AUTOSAR XML (schema 4-0-3)
package /ComponentTypes
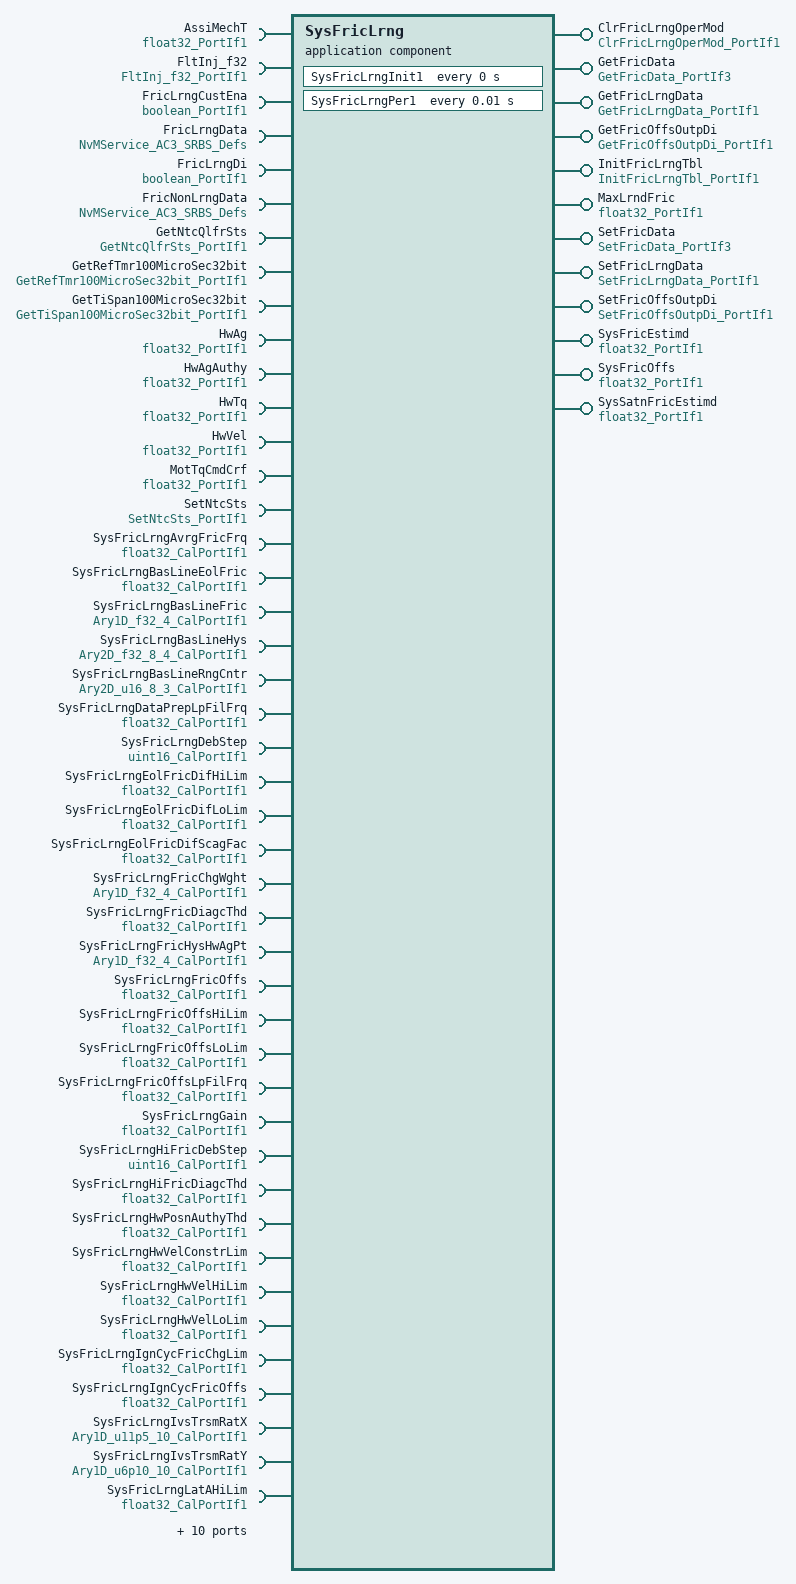
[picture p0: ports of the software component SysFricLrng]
  application sw component type SysFricLrng
    12 x provide port:
      ClrFricLrngOperMod: server-com-spec{operation=Oper, queue-length=1}, provided-interface=ClrFricLrngOperMod_PortIf1
      GetFricData: server-com-spec{operation=Oper, queue-length=1}, provided-interface=GetFricData_PortIf3
      GetFricLrngData: server-com-spec{operation=Oper, queue-length=1}, provided-interface=GetFricLrngData_PortIf1
      GetFricOffsOutpDi: server-com-spec{operation=Oper, queue-length=1}, provided-interface=GetFricOffsOutpDi_PortIf1
      InitFricLrngTbl: server-com-spec{operation=Oper, queue-length=1}, provided-interface=InitFricLrngTbl_PortIf1
      MaxLrndFric: nonqueued-sender-com-spec{data-element=Val, init-value=0}, provided-interface=float32_PortIf1
      SetFricData: server-com-spec{operation=Oper, queue-length=1}, provided-interface=SetFricData_PortIf3
      SetFricLrngData: server-com-spec{operation=Oper, queue-length=1}, provided-interface=SetFricLrngData_PortIf1
      SetFricOffsOutpDi: server-com-spec{operation=Oper, queue-length=1}, provided-interface=SetFricOffsOutpDi_PortIf1
      SysFricEstimd: nonqueued-sender-com-spec{data-element=Val, init-value=0}, provided-interface=float32_PortIf1
      SysFricOffs: nonqueued-sender-com-spec{data-element=Val, init-value=0}, provided-interface=float32_PortIf1
      SysSatnFricEstimd: nonqueued-sender-com-spec{data-element=Val, init-value=0}, provided-interface=float32_PortIf1
    54 x require port:
      AssiMechT: nonqueued-receiver-com-spec{data-element=Val, filter=data-filter-type=ALWAYS, init-value=0}, required-interface=float32_PortIf1
      FltInj_f32: client-com-spec=Oper, required-interface=FltInj_f32_PortIf1
      FricLrngCustEna: nonqueued-receiver-com-spec{data-element=Logl, filter=data-filter-type=ALWAYS, init-value=1}, required-interface=boolean_PortIf1
      FricLrngData: required-com-specs=[EraseBlock, GetErrorStatus, InvalidateNvBlock, ReadBlock, RestoreBlockDefaults, SetRamBlockStatus, WriteBlock], required-interface=NvMService_AC3_SRBS_Defs
      FricLrngDi: nonqueued-receiver-com-spec{data-element=Logl, filter=data-filter-type=ALWAYS, init-value=0}, required-interface=boolean_PortIf1
      FricNonLrngData: required-com-specs=[EraseBlock, GetErrorStatus, InvalidateNvBlock, ReadBlock, RestoreBlockDefaults, SetRamBlockStatus, WriteBlock], required-interface=NvMService_AC3_SRBS_Defs
      GetNtcQlfrSts: client-com-spec=Oper, required-interface=GetNtcQlfrSts_PortIf1
      GetRefTmr100MicroSec32bit: client-com-spec=Oper, required-interface=GetRefTmr100MicroSec32bit_PortIf1
      GetTiSpan100MicroSec32bit: client-com-spec=Oper, required-interface=GetTiSpan100MicroSec32bit_PortIf1
      HwAg: nonqueued-receiver-com-spec{data-element=Val, filter=data-filter-type=ALWAYS, init-value=0}, required-interface=float32_PortIf1
      HwAgAuthy: nonqueued-receiver-com-spec{data-element=Val, filter=data-filter-type=ALWAYS, init-value=0}, required-interface=float32_PortIf1
      HwTq: nonqueued-receiver-com-spec{data-element=Val, filter=data-filter-type=ALWAYS, init-value=0}, required-interface=float32_PortIf1
      HwVel: nonqueued-receiver-com-spec{data-element=Val, filter=data-filter-type=ALWAYS, init-value=0}, required-interface=float32_PortIf1
      MotTqCmdCrf: nonqueued-receiver-com-spec{data-element=Val, filter=data-filter-type=ALWAYS, init-value=0}, required-interface=float32_PortIf1
      SetNtcSts: client-com-spec=Oper, required-interface=SetNtcSts_PortIf1
      SysFricLrngAvrgFricFrq: parameter-require-com-spec{init-value=0.1, parameter=Val}, required-interface=float32_CalPortIf1
      SysFricLrngBasLineEolFric: parameter-require-com-spec{init-value=0, parameter=Val}, required-interface=float32_CalPortIf1
      SysFricLrngBasLineFric: parameter-require-com-spec{init-value=[0, 0, 0, 0], parameter=Ary1D}, required-interface=Ary1D_f32_4_CalPortIf1
      SysFricLrngBasLineHys: parameter-require-com-spec{init-value=8 x [0, 0, 0, 0], parameter=Ary2D}, required-interface=Ary2D_f32_8_4_CalPortIf1
      SysFricLrngBasLineRngCntr: parameter-require-com-spec{init-value=8 x [0, 0, 0], parameter=Ary2D}, required-interface=Ary2D_u16_8_3_CalPortIf1
      SysFricLrngDataPrepLpFilFrq: parameter-require-com-spec{init-value=30, parameter=Val}, required-interface=float32_CalPortIf1
      SysFricLrngDebStep: parameter-require-com-spec{init-value=656, parameter=Val}, required-interface=uint16_CalPortIf1
      SysFricLrngEolFricDifHiLim: parameter-require-com-spec{init-value=1, parameter=Val}, required-interface=float32_CalPortIf1
      SysFricLrngEolFricDifLoLim: parameter-require-com-spec{init-value=-1, parameter=Val}, required-interface=float32_CalPortIf1
      SysFricLrngEolFricDifScagFac: parameter-require-com-spec{init-value=0.8, parameter=Val}, required-interface=float32_CalPortIf1
      SysFricLrngFricChgWght: parameter-require-com-spec{init-value=[1, 1, 1, 1], parameter=Ary1D}, required-interface=Ary1D_f32_4_CalPortIf1
      SysFricLrngFricDiagcThd: parameter-require-com-spec{init-value=15, parameter=Val}, required-interface=float32_CalPortIf1
      SysFricLrngFricHysHwAgPt: parameter-require-com-spec{init-value=[-15, -5, 5, 15], parameter=Ary1D}, required-interface=Ary1D_f32_4_CalPortIf1
      SysFricLrngFricOffs: parameter-require-com-spec{init-value=0, parameter=Val}, required-interface=float32_CalPortIf1
      SysFricLrngFricOffsHiLim: parameter-require-com-spec{init-value=1, parameter=Val}, required-interface=float32_CalPortIf1
      SysFricLrngFricOffsLoLim: parameter-require-com-spec{init-value=-1, parameter=Val}, required-interface=float32_CalPortIf1
      SysFricLrngFricOffsLpFilFrq: parameter-require-com-spec{init-value=4, parameter=Val}, required-interface=float32_CalPortIf1
      SysFricLrngGain: parameter-require-com-spec{init-value=0.2, parameter=Val}, required-interface=float32_CalPortIf1
      SysFricLrngHiFricDebStep: parameter-require-com-spec{init-value=656, parameter=Val}, required-interface=uint16_CalPortIf1
      SysFricLrngHiFricDiagcThd: parameter-require-com-spec{init-value=30, parameter=Val}, required-interface=float32_CalPortIf1
      SysFricLrngHwPosnAuthyThd: parameter-require-com-spec{init-value=0.98, parameter=Val}, required-interface=float32_CalPortIf1
      SysFricLrngHwVelConstrLim: parameter-require-com-spec{init-value=360, parameter=Val}, required-interface=float32_CalPortIf1
      SysFricLrngHwVelHiLim: parameter-require-com-spec{init-value=180, parameter=Val}, required-interface=float32_CalPortIf1
      SysFricLrngHwVelLoLim: parameter-require-com-spec{init-value=10, parameter=Val}, required-interface=float32_CalPortIf1
      SysFricLrngIgnCycFricChgLim: parameter-require-com-spec{init-value=3, parameter=Val}, required-interface=float32_CalPortIf1
      SysFricLrngIgnCycFricOffs: parameter-require-com-spec{init-value=3, parameter=Val}, required-interface=float32_CalPortIf1
      SysFricLrngIvsTrsmRatX: parameter-require-com-spec{init-value=[0, 960, 1920, 2880, 3840, 5760, 8640, 11520, 14400, 17280], parameter=Ary1D}, required-interface=Ary1D_u11p5_10_CalPortIf1
      SysFricLrngIvsTrsmRatY: parameter-require-com-spec{init-value=10 x 24269, parameter=Ary1D}, required-interface=Ary1D_u6p10_10_CalPortIf1
      SysFricLrngLatAHiLim: parameter-require-com-spec{init-value=10, parameter=Val}, required-interface=float32_CalPortIf1
      SysFricLrngLatALoLim: parameter-require-com-spec{init-value=0, parameter=Val}, required-interface=float32_CalPortIf1
      SysFricLrngMaskVehSpd: parameter-require-com-spec{init-value=[1, 1, 1, 1], parameter=Ary1D}, required-interface=Ary1D_boolean_4_CalPortIf1
      SysFricLrngRngCntrThd: parameter-require-com-spec{init-value=65534, parameter=Val}, required-interface=uint16_CalPortIf1
      SysFricLrngThd: parameter-require-com-spec{init-value=1, parameter=Val}, required-interface=uint32_CalPortIf1
      SysFricLrngTHiLim: parameter-require-com-spec{init-value=100, parameter=Val}, required-interface=float32_CalPortIf1
      SysFricLrngTLoLim: parameter-require-com-spec{init-value=0, parameter=Val}, required-interface=float32_CalPortIf1
      SysFricLrngVehSpd: parameter-require-com-spec{init-value=[[0, 5], [60, 80], [80, 100], [100, 120]], parameter=Ary2D}, required-interface=Ary2D_f32_4_2_CalPortIf1
      VehLatA: nonqueued-receiver-com-spec{data-element=Val, filter=data-filter-type=ALWAYS, init-value=0}, required-interface=float32_PortIf1
      VehSpd: nonqueued-receiver-com-spec{data-element=Val, filter=data-filter-type=ALWAYS, init-value=0}, required-interface=float32_PortIf1
      VehSpdVld: nonqueued-receiver-com-spec{data-element=Logl, filter=data-filter-type=ALWAYS, init-value=0}, required-interface=boolean_PortIf1
    behavior SysFricLrng_InternalBehavior
      ar-typed-per-instance-memorys:
        29 x data, all with sw-calibration-access=READ-ONLY:
          AssiMechTLpFil: type=FilLpRec1
          AvrgFricLpFil{1..4}: type=FilLpRec1
          ColTqAry: type=Ary1D_f32_12
          ColTqLpFil: type=FilLpRec1
          EstimdFric: type=float32
          FilAvrgFric: type=Ary1D_f32_4
          FricChgLpFil: type=FilLpRec1
          FricLrngData: type=SysFricDataRec1
          FricLrngOperModPrev: type=SysFricLrngOperMod1
          FricLrngRunOneTi: type=boolean
          FricNonLrngData: type=SysFricNonLrngDataRec1
          FricOffs: type=float32
          FricOffsOutpDi: type=boolean
          HwAgAuthyLpFil: type=FilLpRec1
          HwAgBuf: type=Ary1D_f32_12
          HwAgLpFil: type=FilLpRec1
          HwVelBuf: type=Ary1D_f32_12
          HwVelLpFil: type=FilLpRec1
          LatALpFil: type=FilLpRec1
          PrevMaxRawAvrgFric: type=float32
          RawAvrgFric: type=Ary1D_f32_4
          RefTmrLrngConstr: type=uint32
          SatnAvrgFric: type=Ary1D_f32_4
          SatnEstimdFric: type=float32
          VehBasLineFric: type=Ary1D_f32_4
          VehSpdLpFil: type=FilLpRec1
      8 x operation invoked event:
        OIT_ClrFricLrngOperMod_Oper_ClrFricLrngOperMod_Oper: start-on-event=ClrFricLrngOperMod_Oper, operation=ClrFricLrngOperMod.Oper
        OIT_GetFricData_Oper_GetFricData_Oper: start-on-event=GetFricData_Oper, operation=GetFricData.Oper
        OIT_GetFricLrngData_Oper_GetFricLrngData_Oper: start-on-event=GetFricLrngData_Oper, operation=GetFricLrngData.Oper
        OIT_GetFricOffsOutpDi_Oper_GetFricOffsOutpDi_Oper: start-on-event=GetFricOffsOutpDi_Oper, operation=GetFricOffsOutpDi.Oper
        OIT_InitFricLrngTbl_Oper_InitFricLrngTbl_Oper: start-on-event=InitFricLrngTbl_Oper, operation=InitFricLrngTbl.Oper
        OIT_SetFricData_Oper_SetFricData_Oper: start-on-event=SetFricData_Oper, operation=SetFricData.Oper
        OIT_SetFricLrngData_Oper_SetFricLrngData_Oper: start-on-event=SetFricLrngData_Oper, operation=SetFricLrngData.Oper
        OIT_SetFricOffsOutpDi_Oper_SetFricOffsOutpDi_Oper: start-on-event=SetFricOffsOutpDi_Oper, operation=SetFricOffsOutpDi.Oper
      timing event SysFricLrng_InitEvent: start-on-event=SysFricLrngInit1, period=0
      timing event TMT_SysFricLrngPer1: start-on-event=SysFricLrngPer1, period=0.01
      10 x runnable:
        ClrFricLrngOperMod_Oper
        GetFricData_Oper
        GetFricLrngData_Oper: can-be-invoked-concurrently=true
        GetFricOffsOutpDi_Oper
        InitFricLrngTbl_Oper
        SetFricData_Oper
        SetFricLrngData_Oper
          sync call SC_FricNonLrngData_SetRamBlockStatus: operation=FricNonLrngData.SetRamBlockStatus, timeout=0
        SetFricOffsOutpDi_Oper
        SysFricLrngInit1
          data-send-points:
            access SEND_SysFricOffs_Val: accessed-variable=SysFricOffs.Val
          sync call SC_FricLrngData_SetRamBlockStatus: operation=FricLrngData.SetRamBlockStatus, timeout=0
          sync call SC_GetRefTmr100MicroSec32bit_Oper: operation=GetRefTmr100MicroSec32bit.Oper, timeout=0
          sync call SC_SetNtcSts_Oper: operation=SetNtcSts.Oper, timeout=0
        SysFricLrngPer1
          data-receive-point-by-arguments:
            11 x access:
              REC_AssiMechT_Val: accessed-variable=AssiMechT.Val
              REC_FricLrngCustEna_Logl: accessed-variable=FricLrngCustEna.Logl
              REC_FricLrngDi_Logl: accessed-variable=FricLrngDi.Logl
              REC_HwAg_Val: accessed-variable=HwAg.Val
              REC_HwAgAuthy_Val: accessed-variable=HwAgAuthy.Val
              REC_HwTq_Val: accessed-variable=HwTq.Val
              REC_HwVel_Val: accessed-variable=HwVel.Val
              REC_MotTqCmdCrf_Val: accessed-variable=MotTqCmdCrf.Val
              REC_VehLatA_Val: accessed-variable=VehLatA.Val
              REC_VehSpd_Val: accessed-variable=VehSpd.Val
              REC_VehSpdVld_Logl: accessed-variable=VehSpdVld.Logl
          data-send-points:
            4 x access:
              SEND_MaxLrndFric_Val: accessed-variable=MaxLrndFric.Val
              SEND_SysFricEstimd_Val: accessed-variable=SysFricEstimd.Val
              SEND_SysFricOffs_Val: accessed-variable=SysFricOffs.Val
              SEND_SysSatnFricEstimd_Val: accessed-variable=SysSatnFricEstimd.Val
          5 x sync call, all with timeout=0:
            SC_FltInj_f32_Oper: operation=FltInj_f32.Oper
            SC_GetNtcQlfrSts_Oper: operation=GetNtcQlfrSts.Oper
            SC_GetRefTmr100MicroSec32bit_Oper: operation=GetRefTmr100MicroSec32bit.Oper
            SC_GetTiSpan100MicroSec32bit_Oper: operation=GetTiSpan100MicroSec32bit.Oper
            SC_SetNtcSts_Oper: operation=SetNtcSts.Oper
      swc service dependency NvMFricLrngData
        assigned-datas:
          role=ramBlock, used-data-element=FricLrngData
          role=defaultValue, used-parameter-element=FricLrngDataDft
        assigned-ports:
          port-prototype=FricLrngData, role=NvMService_AC3_SRBS_Defs
          port-prototype=FricLrngData, role=NvMService_AC3_SRBS_Defs
        service-needs:
          nv block needs NvMFricLrngData: n-data-sets=0, readonly=false, reliability=ERROR-DETECTION, resistant-to-changed-sw=true, restore-at-start=true, store-at-shutdown=true, write-only-once=false, writing-frequency=0, writing-priority=LOW
      swc service dependency NvMFricNonLrngData
        assigned-datas:
          role=ramBlock, used-data-element=FricNonLrngData
          role=defaultValue, used-parameter-element=FricNonLrngDataDft
        assigned-ports:
          port-prototype=FricNonLrngData, role=NvMService_AC3_SRBS_Defs
          port-prototype=FricNonLrngData, role=NvMService_AC3_SRBS_Defs
        service-needs:
          nv block needs NvMFricNonLrngData: n-data-sets=0, readonly=false, reliability=ERROR-DETECTION, resistant-to-changed-sw=true, restore-at-start=true, store-at-shutdown=true, write-only-once=false, writing-frequency=0, writing-priority=LOW
      shared-parameters:
        parameter data prototype FricLrngDataDft: sw-calibration-access=READ-WRITE, type=SysFricDataRec1, init-value=fields=[FricOffs:0.0, BasLineFric:[0.0, 0.0, 0.0, 0.0], VehLrndFric:[0.0, 0.0, 0.0, 0.0], Hys:8 x [0.0, 0.0, 0.0, 0.0], RngCntr:8 x [0, 0, 0], SysFricLrngOperMod:0]
        parameter data prototype FricNonLrngDataDft: sw-calibration-access=READ-WRITE, type=SysFricNonLrngDataRec1, init-value=fields=[EolFric:0.0, EnaFricLrng:0, EnaFricOffsOutp:0]
  swc implementation SysFricLrng_Implementation: behavior=SysFricLrng_InternalBehavior
    code-descriptors:
      code Default: artifact-descriptors=autosar-engineering-object={short-label=Default, category=SWSRC}
